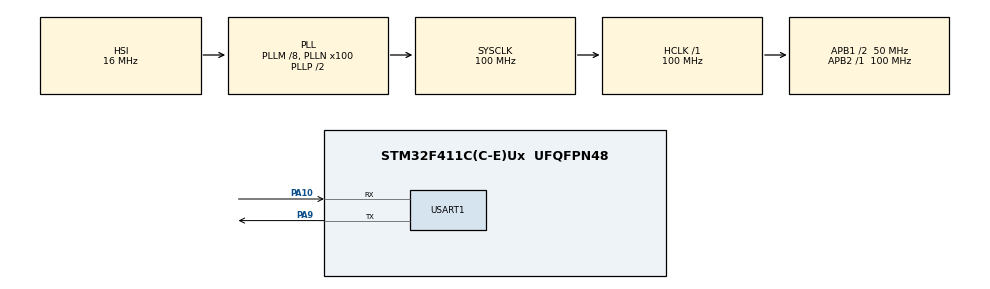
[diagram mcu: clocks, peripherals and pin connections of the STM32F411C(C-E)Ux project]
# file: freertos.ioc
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FREERTOS.Tasks01=defaultTask,24,128,StartDefaultTask,Default,NULL,Dynamic,NULL,NULL
Mcu.Family=STM32F4
Mcu.Name=STM32F411C(C-E)Ux
Mcu.Package=UFQFPN48
NVIC.PriorityGroup=NVIC_PRIORITYGROUP_4
NVIC.TIM1_UP_TIM10_IRQn=true\:15\:0\:false\:false\:true\:false\:false\:true\:true
NVIC.TimeBase=TIM1_UP_TIM10_IRQn
NVIC.TimeBaseIP=TIM1
PA10.Mode=Asynchronous
PA10.Signal=USART1_RX
PA13.Mode=Serial_Wire
PA13.Signal=SYS_JTMS-SWDIO
PA14.Mode=Serial_Wire
PA14.Signal=SYS_JTCK-SWCLK
PA9.Mode=Asynchronous
PA9.Signal=USART1_TX
PC14-OSC32_IN.Mode=LSE-External-Oscillator
PC14-OSC32_IN.Signal=RCC_OSC32_IN
PC15-OSC32_OUT.Mode=LSE-External-Oscillator
PC15-OSC32_OUT.Signal=RCC_OSC32_OUT
PH0\ -\ OSC_IN.Mode=HSE-External-Oscillator
PH0\ -\ OSC_IN.Signal=RCC_OSC_IN
PH1\ -\ OSC_OUT.Mode=HSE-External-Oscillator
PH1\ -\ OSC_OUT.Signal=RCC_OSC_OUT
ProjectManager.HeapSize=0x200
ProjectManager.StackSize=0x400
ProjectManager.TargetToolchain=MDK-ARM V5.32
RCC.48MHZClocksFreq_Value=50000000
RCC.AHBFreq_Value=100000000
RCC.APB1CLKDivider=RCC_HCLK_DIV2
RCC.APB1Freq_Value=50000000
RCC.APB1TimFreq_Value=100000000
RCC.APB2Freq_Value=100000000
RCC.APB2TimFreq_Value=100000000
RCC.CortexFreq_Value=100000000
RCC.HCLKFreq_Value=100000000
RCC.HSE_VALUE=25000000
RCC.HSI_VALUE=16000000
RCC.PLLM=8
RCC.PLLN=100
RCC.SYSCLKFreq_VALUE=100000000
RCC.SYSCLKSource=RCC_SYSCLKSOURCE_PLLCLK
RCC.VCOOutputFreq_Value=200000000
USART1.VirtualMode=VM_ASYNC
VP_FREERTOS_VS_CMSIS_V2.Mode=CMSIS_V2
VP_SYS_VS_tim1.Mode=TIM1
board=custom

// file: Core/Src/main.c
/* USER CODE BEGIN Header */
/**
  ******************************************************************************
  * @file           : main.c
  * @brief          : Main program body
  ******************************************************************************
  * @attention
  *
  * Copyright (c) 2026 STMicroelectronics.
  * All rights reserved.
  *
  * This software is licensed under terms that can be found in the LICENSE file
  * in the root directory of this software component.
  * If no LICENSE file comes with this software, it is provided AS-IS.
  *
  ******************************************************************************
  */
/* USER CODE END Header */
#include "main.h"
#include "cmsis_os.h"
#include "usart.h"
#include "gpio.h"
#include "FreeRTOS.h"
#include "task.h"

void SystemClock_Config(void);
void MX_FREERTOS_Init(void);

uint32_t a = 0, b = 0, c = 0;
// 任务1：每100ms自增a，并延时
void vTask1(void *pvParam)
{
    while (1)
    {
        ++a;
        uint32_t startime = xTaskGetTickCount();
        uint32_t endtime = xTaskGetTickCount();
        printf("task1: %dms\n", endtime - starttime);
        vTaskDelay(pdMS_TO_TICKS(100));  // 延时100ms
        printf("task1: %d\n", a);
    }
}

// 任务2：无限循环增加b
void vTask2(void *pvParam)
{
    while (1)
    {
        ++b;
    }
}

// 任务3：无限循环增加c
void vTask3(void *pvParam)
{
    while (1)
    {
        ++c;
    }
}

int main(void)
{

  /* MCU Configuration--------------------------------------------------------*/
  HAL_Init();

  /* Configure the system clock */
  SystemClock_Config();

  /* Initialize all configured peripherals */
  MX_GPIO_Init();
  MX_USART1_UART_Init();

  // 初始化 FreeRTOS 内核（不需要 osKernelInitialize）
  // 注意：FreeRTOS 不需要显式初始化，直接创建任务即可

  // 创建任务
  xTaskCreate(vTask1, "task1", 100, NULL, 1, NULL);
  xTaskCreate(vTask2, "task2", 100, NULL, 1, NULL);
  xTaskCreate(vTask3, "task3", 100, NULL, 1, NULL);

  // 启动调度器
  vTaskStartScheduler();

  // 如果调度器启动失败，会进入这里（理论上不会）
  while (1)
  {
    /* USER CODE END WHILE */
  }
}

void SystemClock_Config(void)
{
  RCC_OscInitTypeDef RCC_OscInitStruct = {0};
  RCC_ClkInitTypeDef RCC_ClkInitStruct = {0};

  /** Configure the main internal regulator output voltage
  */
  __HAL_RCC_PWR_CLK_ENABLE();
  __HAL_PWR_VOLTAGESCALING_CONFIG(PWR_REGULATOR_VOLTAGE_SCALE1);

  /** Initializes the RCC Oscillators according to the specified parameters
  * in the RCC_OscInitTypeDef structure.
  */
  RCC_OscInitStruct.OscillatorType = RCC_OSCILLATORTYPE_HSI;
  RCC_OscInitStruct.HSIState = RCC_HSI_ON;
  RCC_OscInitStruct.HSICalibrationValue = RCC_HSICALIBRATION_DEFAULT;
  RCC_OscInitStruct.PLL.PLLState = RCC_PLL_ON;
  RCC_OscInitStruct.PLL.PLLSource = RCC_PLLSOURCE_HSI;
  RCC_OscInitStruct.PLL.PLLM = 8;
  RCC_OscInitStruct.PLL.PLLN = 100;
  RCC_OscInitStruct.PLL.PLLP = RCC_PLLP_DIV2;
  RCC_OscInitStruct.PLL.PLLQ = 4;
  if (HAL_RCC_OscConfig(&RCC_OscInitStruct) != HAL_OK)
  {
    Error_Handler();
  }

  /** Initializes the CPU, AHB and APB buses clocks
  */
  RCC_ClkInitStruct.ClockType = RCC_CLOCKTYPE_HCLK|RCC_CLOCKTYPE_SYSCLK
                              |RCC_CLOCKTYPE_PCLK1|RCC_CLOCKTYPE_PCLK2;
  RCC_ClkInitStruct.SYSCLKSource = RCC_SYSCLKSOURCE_PLLCLK;
  RCC_ClkInitStruct.AHBCLKDivider = RCC_SYSCLK_DIV1;
  RCC_ClkInitStruct.APB1CLKDivider = RCC_HCLK_DIV2;
  RCC_ClkInitStruct.APB2CLKDivider = RCC_HCLK_DIV1;

  if (HAL_RCC_ClockConfig(&RCC_ClkInitStruct, FLASH_LATENCY_3) != HAL_OK)
  {
    Error_Handler();
  }
}

void HAL_TIM_PeriodElapsedCallback(TIM_HandleTypeDef *htim)
{
  if (htim->Instance == TIM1) {
    HAL_IncTick();
  }
}

void Error_Handler(void)
{
  __disable_irq();
  while (1)
  {
  }
}

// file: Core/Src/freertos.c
/* USER CODE BEGIN Header */
/**
  ******************************************************************************
  * File Name          : freertos.c
  * Description        : Code for freertos applications
  ******************************************************************************
  * @attention
  *
  * Copyright (c) 2026 STMicroelectronics.
  * All rights reserved.
  *
  * This software is licensed under terms that can be found in the LICENSE file
  * in the root directory of this software component.
  * If no LICENSE file comes with this software, it is provided AS-IS.
  *
  ******************************************************************************
  */
/* USER CODE END Header */

#include "FreeRTOS.h"
#include "task.h"
#include "main.h"
#include "cmsis_os.h"

/* USER CODE BEGIN Includes */
#include "stdio.h"
#include "usart.h"
/* USER CODE END Includes */

/* USER CODE BEGIN PTD */
extern UART_HandleTypeDef huart1;

/* USER CODE END PTD */

/* Definitions for defaultTask */
osThreadId_t defaultTaskHandle;
const osThreadAttr_t defaultTask_attributes = {
  .name = "defaultTask",
  .stack_size = 128 * 4,
  .priority = (osPriority_t) osPriorityNormal,
};

void StartDefaultTask(void *argument);

void MX_FREERTOS_Init(void); /* (MISRA C 2004 rule 8.1) */

void MX_FREERTOS_Init(void) {

  /* Create the thread(s) */
  /* creation of defaultTask */
  defaultTaskHandle = osThreadNew(StartDefaultTask, NULL, &defaultTask_attributes);

}

void StartDefaultTask(void *argument)
{
  /* USER CODE BEGIN StartDefaultTask */
  /* Infinite loop */
  for(;;)
  {
		printf("HELLO World\r\n");
    osDelay(1);
  }
  /* USER CODE END StartDefaultTask */
}

/* USER CODE BEGIN Application */
int fputc(int ch, FILE *f)
{
	HAL_UART_Transmit(&huart1,(uint8_t *)&ch, 1, 0xFFFF);
}
/* USER CODE END Application */
